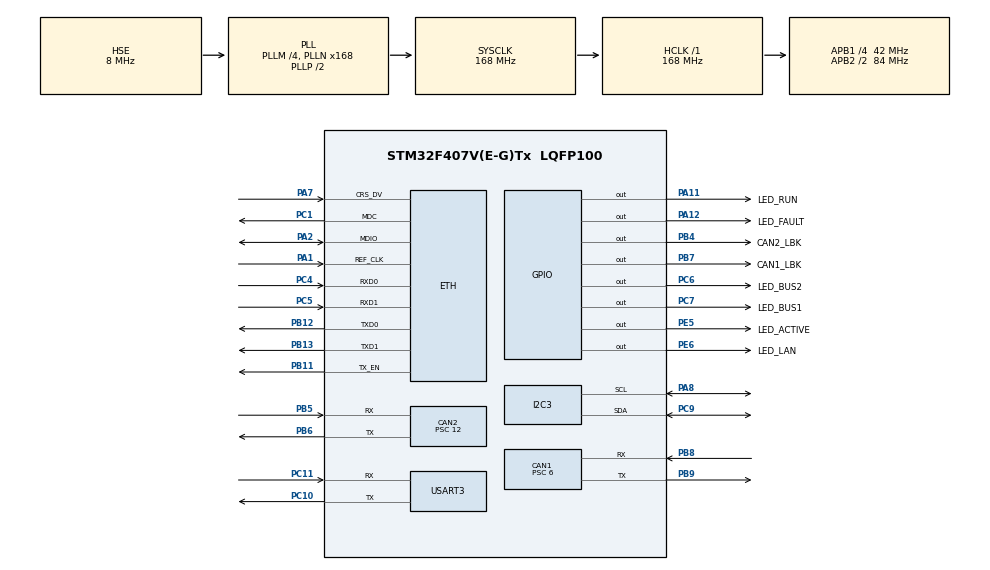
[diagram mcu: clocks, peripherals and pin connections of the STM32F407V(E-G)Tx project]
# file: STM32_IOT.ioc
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CAN1.BS1=CAN_BS1_11TQ
CAN1.BS2=CAN_BS2_2TQ
CAN1.CalculateBaudRate=500000
CAN1.CalculateTimeBit=2000
CAN1.CalculateTimeQuantum=142.85714285714286
CAN1.NART=ENABLE
CAN1.Prescaler=6
CAN2.BS1=CAN_BS1_11TQ
CAN2.BS2=CAN_BS2_2TQ
CAN2.CalculateBaudRate=250000
CAN2.CalculateTimeBit=4000
CAN2.CalculateTimeQuantum=285.7142857142857
CAN2.NART=ENABLE
CAN2.Prescaler=12
ETH.MediaInterface=HAL_ETH_RMII_MODE
LWIP.BSP.number=1
LWIP.CMSIS_VERSION-Enabled=1
LWIP.HTTPD_USE_CUSTOM_FSDATA=1
LWIP.IP_ADDRESS=192.168.010.010
LWIP.LWIP_DHCP=0
LWIP.LWIP_HTTPD=1
LWIP.LWIP_HTTPD_CGI=1
LWIP.LWIP_HTTPD_SSI=1
LWIP.NETMASK_ADDRESS=255.255.255.000
LWIP.Version=v2.1.2_Cube
LWIP0.BSP.STBoard=false
LWIP0.BSP.api=BSP_COMPONENT_DRIVER
LWIP0.BSP.component=DP83848
LWIP0.BSP.instance=DP83848
LWIP0.BSP.name=Driver_PHY
LWIP0.BSP.semaphore=S_DP83848
LWIP0.BSP.solution=DP83848
Mcu.Family=STM32F4
Mcu.Name=STM32F407V(E-G)Tx
Mcu.Package=LQFP100
NVIC.CAN1_RX0_IRQn=true\:0\:0\:false\:false\:true\:true\:true\:true
NVIC.CAN1_RX1_IRQn=true\:0\:0\:false\:false\:true\:true\:true\:true
NVIC.CAN1_SCE_IRQn=true\:0\:0\:false\:false\:true\:true\:true\:true
NVIC.CAN2_RX0_IRQn=true\:0\:0\:false\:false\:true\:true\:true\:true
NVIC.CAN2_RX1_IRQn=true\:0\:0\:false\:false\:true\:true\:true\:true
NVIC.CAN2_SCE_IRQn=true\:0\:0\:false\:false\:true\:true\:true\:true
NVIC.ETH_IRQn=true\:0\:0\:false\:false\:true\:true\:true\:true
NVIC.ETH_WKUP_IRQn=true\:0\:0\:false\:false\:true\:true\:true\:true
NVIC.PriorityGroup=NVIC_PRIORITYGROUP_4
NVIC.USART3_IRQn=true\:0\:0\:false\:false\:true\:true\:true\:true
PA1.Mode=RMII
PA1.Signal=ETH_REF_CLK
PA11.GPIO_Label=LED_RUN
PA11.Signal=GPIO_Output
PA12.GPIO_Label=LED_FAULT
PA12.Signal=GPIO_Output
PA13.Mode=Serial_Wire
PA13.Signal=SYS_JTMS-SWDIO
PA14.Mode=Serial_Wire
PA14.Signal=SYS_JTCK-SWCLK
PA2.Mode=RMII
PA2.Signal=ETH_MDIO
PA7.Mode=RMII
PA7.Signal=ETH_CRS_DV
PA8.Mode=I2C
PA8.Signal=I2C3_SCL
PB11.Mode=RMII
PB11.Signal=ETH_TX_EN
PB12.Mode=RMII
PB12.Signal=ETH_TXD0
PB13.Mode=RMII
PB13.Signal=ETH_TXD1
PB4.GPIO_Label=CAN2_LBK
PB4.GPIO_ModeDefaultOutputPP=GPIO_MODE_OUTPUT_PP
PB4.GPIO_PuPd=GPIO_NOPULL
PB4.Signal=GPIO_Output
PB5.Mode=CAN_Activate
PB5.Signal=CAN2_RX
PB6.Mode=CAN_Activate
PB6.Signal=CAN2_TX
PB7.GPIO_Label=CAN1_LBK
PB7.Signal=GPIO_Output
PB8.Mode=CAN_Activate
PB8.Signal=CAN1_RX
PB9.Mode=CAN_Activate
PB9.Signal=CAN1_TX
PC1.Mode=RMII
PC1.Signal=ETH_MDC
PC10.GPIO_PuPd=GPIO_PULLUP
PC10.Mode=Asynchronous
PC10.Signal=USART3_TX
PC11.GPIO_PuPd=GPIO_PULLUP
PC11.Mode=Asynchronous
PC11.Signal=USART3_RX
PC14-OSC32_IN.Mode=LSE-External-Oscillator
PC14-OSC32_IN.Signal=RCC_OSC32_IN
PC15-OSC32_OUT.Mode=LSE-External-Oscillator
PC15-OSC32_OUT.Signal=RCC_OSC32_OUT
PC4.Mode=RMII
PC4.Signal=ETH_RXD0
PC5.Mode=RMII
PC5.Signal=ETH_RXD1
PC6.GPIO_Label=LED_BUS2
PC6.Signal=GPIO_Output
PC7.GPIO_Label=LED_BUS1
PC7.Signal=GPIO_Output
PC9.Mode=I2C
PC9.Signal=I2C3_SDA
PE5.GPIO_Label=LED_ACTIVE
PE5.Signal=GPIO_Output
PE6.GPIO_Label=LED_LAN
PE6.Signal=GPIO_Output
PH0-OSC_IN.Mode=HSE-External-Oscillator
PH0-OSC_IN.Signal=RCC_OSC_IN
PH1-OSC_OUT.Mode=HSE-External-Oscillator
PH1-OSC_OUT.Signal=RCC_OSC_OUT
ProjectManager.HeapSize=0x1000
ProjectManager.StackSize=0x2000
ProjectManager.TargetToolchain=MDK-ARM V5.32
RCC.48MHZClocksFreq_Value=84000000
RCC.AHBFreq_Value=168000000
RCC.APB1CLKDivider=RCC_HCLK_DIV4
RCC.APB1Freq_Value=42000000
RCC.APB1TimFreq_Value=84000000
RCC.APB2CLKDivider=RCC_HCLK_DIV2
RCC.APB2Freq_Value=84000000
RCC.APB2TimFreq_Value=168000000
RCC.CortexFreq_Value=168000000
RCC.DATA_CACHE_ENABLE=1
RCC.HCLKFreq_Value=168000000
RCC.HSE_VALUE=8000000
RCC.HSI_VALUE=16000000
RCC.INSTRUCTION_CACHE_ENABLE=1
RCC.PLLM=4
RCC.PLLN=168
RCC.PLLSourceVirtual=RCC_PLLSOURCE_HSE
RCC.SYSCLKFreq_VALUE=168000000
RCC.SYSCLKSource=RCC_SYSCLKSOURCE_PLLCLK
RCC.VCOOutputFreq_Value=336000000
USART3.OverSampling=UART_OVERSAMPLING_16
USART3.VirtualMode=VM_ASYNC
VP_LWIP_VS_Enabled.Mode=Enabled
board=custom

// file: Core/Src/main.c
/* USER CODE BEGIN Header */
/**
  ******************************************************************************
  * @file           : main.c
  * @brief          : Main program body
  ******************************************************************************
  * @attention
  *
  * Copyright (c) 2025 STMicroelectronics.
  * All rights reserved.
  *
  * This software is licensed under terms that can be found in the LICENSE file
  * in the root directory of this software component.
  * If no LICENSE file comes with this software, it is provided AS-IS.
  *
  ******************************************************************************
  */
/* USER CODE END Header */
#include "main.h"
#include "can.h"
#include "i2c.h"
#include "lwip.h"
#include "usart.h"
#include "gpio.h"

/* USER CODE BEGIN Includes */
#include "http_cgi_ssi.h"
/* USER CODE END Includes */

void SystemClock_Config(void);

int main(void)
{

  /* MCU Configuration--------------------------------------------------------*/

  /* Reset of all peripherals, Initializes the Flash interface and the Systick. */
  HAL_Init();

  /* Configure the system clock */
  SystemClock_Config();

  /* Initialize all configured peripherals */
  MX_GPIO_Init();
  MX_USART3_UART_Init();
  MX_LWIP_Init();
  MX_I2C3_Init();
  MX_CAN1_Init();
  MX_CAN2_Init();
  /* USER CODE BEGIN 2 */
 /* Http webserver Init */
  http_server_init();
  /* USER CODE END 2 */

  /* Infinite loop */
  /* USER CODE BEGIN WHILE */
  while (1)
  {
    MX_LWIP_Process();
    HAL_Delay(1);
    /* USER CODE END WHILE */

  }
}

void SystemClock_Config(void)
{
  RCC_OscInitTypeDef RCC_OscInitStruct = {0};
  RCC_ClkInitTypeDef RCC_ClkInitStruct = {0};

  /** Configure the main internal regulator output voltage
  */
  __HAL_RCC_PWR_CLK_ENABLE();
  __HAL_PWR_VOLTAGESCALING_CONFIG(PWR_REGULATOR_VOLTAGE_SCALE1);

  /** Initializes the RCC Oscillators according to the specified parameters
  * in the RCC_OscInitTypeDef structure.
  */
  RCC_OscInitStruct.OscillatorType = RCC_OSCILLATORTYPE_HSE;
  RCC_OscInitStruct.HSEState = RCC_HSE_ON;
  RCC_OscInitStruct.PLL.PLLState = RCC_PLL_ON;
  RCC_OscInitStruct.PLL.PLLSource = RCC_PLLSOURCE_HSE;
  RCC_OscInitStruct.PLL.PLLM = 4;
  RCC_OscInitStruct.PLL.PLLN = 168;
  RCC_OscInitStruct.PLL.PLLP = RCC_PLLP_DIV2;
  RCC_OscInitStruct.PLL.PLLQ = 4;
  if (HAL_RCC_OscConfig(&RCC_OscInitStruct) != HAL_OK)
  {
    Error_Handler();
  }

  /** Initializes the CPU, AHB and APB buses clocks
  */
  RCC_ClkInitStruct.ClockType = RCC_CLOCKTYPE_HCLK|RCC_CLOCKTYPE_SYSCLK
                              |RCC_CLOCKTYPE_PCLK1|RCC_CLOCKTYPE_PCLK2;
  RCC_ClkInitStruct.SYSCLKSource = RCC_SYSCLKSOURCE_PLLCLK;
  RCC_ClkInitStruct.AHBCLKDivider = RCC_SYSCLK_DIV1;
  RCC_ClkInitStruct.APB1CLKDivider = RCC_HCLK_DIV4;
  RCC_ClkInitStruct.APB2CLKDivider = RCC_HCLK_DIV2;

  if (HAL_RCC_ClockConfig(&RCC_ClkInitStruct, FLASH_LATENCY_5) != HAL_OK)
  {
    Error_Handler();
  }
}

void Error_Handler(void)
{
  __disable_irq();
  while (1)
  {
  }
}
